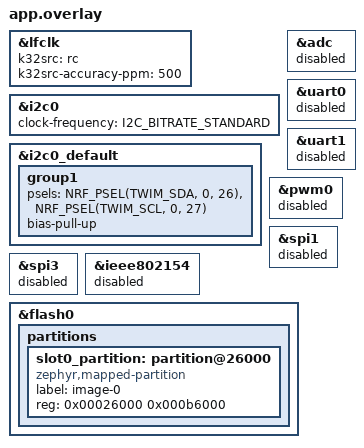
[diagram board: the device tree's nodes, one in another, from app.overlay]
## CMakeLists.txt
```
cmake_minimum_required(VERSION 3.20.0)
find_package(Zephyr REQUIRED HINTS $ENV{ZEPHYR_BASE})
project(nu40_ble_lcd)
target_include_directories(app PRIVATE include ../wireless_lcd_common/include)
target_sources(app PRIVATE src/main.c src/lcd_device.c src/lcd_command.c)
target_sources_ifdef(CONFIG_LCD_SSD1306_PROFILE app PRIVATE src/oled_device.c)
```

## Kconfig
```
mainmenu "NU40 BLE LCD"

config LCD_SSD1306_PROFILE
	bool "Enable an explicitly verified SSD1306 128x32 I2C OLED profile"
	default n
	help
	  SSD1306 only: 128x32, 16x4 ASCII cells, internal charge pump, no reset GPIO.
	  Confirm actual controller, geometry, address and voltage before enabling.

config LCD_PCF8574_PROFILE
	bool "Enable an explicitly verified HD44780 / PCF8574 backpack profile"
	default n
	depends on !LCD_SSD1306_PROFILE
	help
	  Enable only after confirming the LCD controller, supply/logic levels,
	  expander address, pin mapping, geometry and physical I2C wiring.

config LCD_COLUMNS
	int "LCD columns"
	default 16
	range 1 20

config LCD_ROWS
	int "LCD rows (driver supports 1, 2, or 4)"
	default 2
	range 1 4

config LCD_I2C_ADDRESS
	hex "Explicitly configured I2C display address"
	default 0x27
	range 0x20 0x3f

config LCD_RS_BIT
	int "Expander bit for RS"
	default 0
	range 0 7
config LCD_RW_BIT
	int "Expander bit for RW (always driven LOW)"
	default 1
	range 0 7
config LCD_ENABLE_BIT
	int "Expander bit for Enable"
	default 2
	range 0 7
config LCD_BACKLIGHT_BIT
	int "Expander bit for backlight"
	default 3
	range 0 7
config LCD_DB4_BIT
	int "Expander bit for DB4"
	default 4
	range 0 7
config LCD_DB5_BIT
	int "Expander bit for DB5"
	default 5
	range 0 7
config LCD_DB6_BIT
	int "Expander bit for DB6"
	default 6
	range 0 7
config LCD_DB7_BIT
	int "Expander bit for DB7"
	default 7
	range 0 7
config LCD_BACKLIGHT_ACTIVE_HIGH
	bool "Backlight is active HIGH"
	default y

config LCD_LEGACY_DFU
	bool "Permit reset entry into verified Adafruit 0.9.1 legacy BLE DFU"
	default n
	help
	  Only enable after verifying this board's preserved S140/Adafruit OTA
	  bootloader and recovery path. This enables a reset trigger, not an OTA
	  transfer implementation, signatures, rollback, or MCUboot support.

source "Kconfig.zephyr"
```

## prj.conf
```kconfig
CONFIG_GPIO=y
CONFIG_I2C=y
CONFIG_PINCTRL=y
CONFIG_CONSOLE=y
CONFIG_PRINTK=y
CONFIG_BT=y
CONFIG_BT_PERIPHERAL=y
CONFIG_BT_DEVICE_NAME="MZSZ-LCD"
CONFIG_BT_MAX_CONN=1
CONFIG_BT_SMP=n
CONFIG_MAIN_STACK_SIZE=4096
CONFIG_SYSTEM_WORKQUEUE_STACK_SIZE=2048
CONFIG_BUILD_OUTPUT_UF2=y
CONFIG_USE_DT_CODE_PARTITION=y
CONFIG_LCD_PCF8574_PROFILE=n
CONFIG_LCD_SSD1306_PROFILE=n
CONFIG_LCD_LEGACY_DFU=n
```

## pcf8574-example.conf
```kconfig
# EXAMPLE ONLY: confirm controller, geometry, address, mapping and voltage first.
CONFIG_LCD_PCF8574_PROFILE=y
CONFIG_LCD_COLUMNS=16
CONFIG_LCD_ROWS=2
CONFIG_LCD_I2C_ADDRESS=0x27
CONFIG_LCD_RS_BIT=0
CONFIG_LCD_RW_BIT=1
CONFIG_LCD_ENABLE_BIT=2
CONFIG_LCD_BACKLIGHT_BIT=3
CONFIG_LCD_DB4_BIT=4
CONFIG_LCD_DB5_BIT=5
CONFIG_LCD_DB6_BIT=6
CONFIG_LCD_DB7_BIT=7
CONFIG_LCD_BACKLIGHT_ACTIVE_HIGH=y
```

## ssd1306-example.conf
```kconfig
# EXAMPLE ONLY: confirm SSD1306, 128x32, 0x3C and compatible I2C logic levels.
CONFIG_LCD_SSD1306_PROFILE=y
CONFIG_LCD_PCF8574_PROFILE=n
CONFIG_LCD_COLUMNS=16
CONFIG_LCD_ROWS=4
CONFIG_LCD_I2C_ADDRESS=0x3c
```

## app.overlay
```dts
/* Legacy NRF52BOOT 0.9.1 / S140 6.1.1 only. Preserve MBR, SD, NVS and bootloader. */
&lfclk {
	k32src = "rc";
	k32src-accuracy-ppm = <500>;
};

&i2c0 {
	status = "okay";
	clock-frequency = <I2C_BITRATE_STANDARD>;
};
&i2c0_default {
	group1 {
		psels = <NRF_PSEL(TWIM_SDA, 0, 26)>, <NRF_PSEL(TWIM_SCL, 0, 27)>;
		bias-pull-up;
	};
};

&adc { status = "disabled"; };
&uart0 { status = "disabled"; };
&uart1 { status = "disabled"; };
&pwm0 { status = "disabled"; };
&spi1 { status = "disabled"; };
&spi3 { status = "disabled"; };
&ieee802154 { status = "disabled"; };

&flash0 {
	partitions {
		/delete-node/ partition@1000;
		/delete-node/ partition@10000;
		/delete-node/ partition@76000;
		slot0_partition: partition@26000 {
			compatible = "zephyr,mapped-partition";
			label = "image-0";
			reg = <0x00026000 0x000b6000>;
		};
	};
};
```

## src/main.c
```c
#include <errno.h>
#include <string.h>

#include <zephyr/bluetooth/bluetooth.h>
#include <zephyr/bluetooth/conn.h>
#include <zephyr/bluetooth/gatt.h>
#include <zephyr/bluetooth/uuid.h>
#include <zephyr/device.h>
#include <zephyr/drivers/i2c.h>
#include <zephyr/kernel.h>
#include <zephyr/sys/atomic.h>
#include <zephyr/sys/printk.h>

#include "lcd_command.h"
#include "lcd_device.h"
#include "oled_device.h"

#if defined(CONFIG_LCD_LEGACY_DFU)
#include <hal/nrf_power.h>
#endif

#define LCD_ENCODE_UUID(...) BT_UUID_128_ENCODE(__VA_ARGS__)
#define LCD_SERVICE_UUID_VAL LCD_ENCODE_UUID(LCD_SERVICE_UUID_PARTS)
#define LCD_COMMAND_UUID_VAL LCD_ENCODE_UUID(LCD_COMMAND_UUID_PARTS)
#define LCD_STATUS_UUID_VAL LCD_ENCODE_UUID(LCD_STATUS_UUID_PARTS)
#define STATUS_ATTR_INDEX 4
#define LCD_PROFILE_CONFIGURED (IS_ENABLED(CONFIG_LCD_PCF8574_PROFILE) || \
				IS_ENABLED(CONFIG_LCD_SSD1306_PROFILE))
BUILD_ASSERT(CONFIG_LCD_ROWS == 1 || CONFIG_LCD_ROWS == 2 || CONFIG_LCD_ROWS == 4,
	     "Text profiles support 1, 2, or 4 rows");
BUILD_ASSERT(LCD_COMMAND_MAX_SIZE <= 20 && LCD_STATUS_SIZE <= 20,
	     "LCD protocol must fit the default ATT MTU");

struct pending_command {
	struct lcd_command command;
	struct bt_conn *connection;
	atomic_val_t generation;
};

K_MSGQ_DEFINE(command_queue, sizeof(struct pending_command), 4, 4);
static atomic_t connection_generation;
static struct k_spinlock status_lock;
#if defined(CONFIG_LCD_SSD1306_PROFILE)
static struct oled_device oled;
BUILD_ASSERT(CONFIG_LCD_COLUMNS == OLED_COLUMNS && CONFIG_LCD_ROWS == OLED_ROWS,
	     "SSD1306 128x32 profile requires 16x4 text cells");
#else
static struct lcd_device lcd;
#endif
static uint8_t latest_status[LCD_STATUS_SIZE] = {
	LCD_PROTOCOL_VERSION, LCD_OP_STATUS, 0, 0, LCD_RESULT_UNCONFIGURED, 0, 0, 0,
};

static const struct bt_uuid_128 service_uuid = BT_UUID_INIT_128(LCD_SERVICE_UUID_VAL);
static const struct bt_uuid_128 command_uuid = BT_UUID_INIT_128(LCD_COMMAND_UUID_VAL);
static const struct bt_uuid_128 status_uuid = BT_UUID_INIT_128(LCD_STATUS_UUID_VAL);

static ssize_t read_status(struct bt_conn *conn, const struct bt_gatt_attr *attr,
			   void *buffer, uint16_t length, uint16_t offset)
{
	uint8_t snapshot[LCD_STATUS_SIZE];
	k_spinlock_key_t key = k_spin_lock(&status_lock);

	memcpy(snapshot, latest_status, sizeof(snapshot));
	k_spin_unlock(&status_lock, key);
	return bt_gatt_attr_read(conn, attr, buffer, length, offset, snapshot, sizeof(snapshot));
}

static ssize_t write_command(struct bt_conn *conn, const struct bt_gatt_attr *attr,
			     const void *buffer, uint16_t length, uint16_t offset,
			     uint8_t flags)
{
	struct pending_command item = {0};
	int rc;

	ARG_UNUSED(attr);
	if (offset != 0) {
		return BT_GATT_ERR(BT_ATT_ERR_INVALID_OFFSET);
	}
	if (flags & (BT_GATT_WRITE_FLAG_PREPARE | BT_GATT_WRITE_FLAG_EXECUTE)) {
		return BT_GATT_ERR(BT_ATT_ERR_NOT_SUPPORTED);
	}
	if (length < LCD_COMMAND_HEADER_SIZE || length > LCD_COMMAND_MAX_SIZE) {
		return BT_GATT_ERR(BT_ATT_ERR_INVALID_ATTRIBUTE_LEN);
	}
	rc = lcd_command_parse(buffer, length, CONFIG_LCD_COLUMNS, CONFIG_LCD_ROWS,
			       &item.command);
	if (rc != 0) {
		return BT_GATT_ERR(BT_ATT_ERR_VALUE_NOT_ALLOWED);
	}
	item.connection = bt_conn_ref(conn);
	item.generation = atomic_get(&connection_generation);
	rc = k_msgq_put(&command_queue, &item, K_NO_WAIT);
	if (rc != 0) {
		bt_conn_unref(item.connection);
		return BT_GATT_ERR(BT_ATT_ERR_INSUFFICIENT_RESOURCES);
	}
	return length;
}

BT_GATT_SERVICE_DEFINE(lcd_service,
	BT_GATT_PRIMARY_SERVICE(&service_uuid),
	BT_GATT_CHARACTERISTIC(&command_uuid.uuid, BT_GATT_CHRC_WRITE,
			       BT_GATT_PERM_WRITE, NULL, write_command, NULL),
	BT_GATT_CHARACTERISTIC(&status_uuid.uuid, BT_GATT_CHRC_READ | BT_GATT_CHRC_NOTIFY,
			       BT_GATT_PERM_READ, read_status, NULL, NULL),
	BT_GATT_CCC(NULL, BT_GATT_PERM_READ | BT_GATT_PERM_WRITE),
);

static const struct bt_data advertising[] = {
	BT_DATA_BYTES(BT_DATA_FLAGS, BT_LE_AD_GENERAL | BT_LE_AD_NO_BREDR),
	BT_DATA_BYTES(BT_DATA_UUID128_ALL, LCD_SERVICE_UUID_VAL),
};
static const struct bt_data scan_response[] = {
	BT_DATA(BT_DATA_NAME_COMPLETE, CONFIG_BT_DEVICE_NAME, sizeof(CONFIG_BT_DEVICE_NAME) - 1),
};

static void advertising_work(struct k_work *work)
{
	int rc;

	ARG_UNUSED(work);
	rc = bt_le_adv_start(BT_LE_ADV_CONN_FAST_1, advertising, ARRAY_SIZE(advertising),
			     scan_response, ARRAY_SIZE(scan_response));
	if (rc != 0 && rc != -EALREADY) {
		printk("LCD BLE advertising error=%d\n", rc);
	}
}
K_WORK_DEFINE(advertising_restart, advertising_work);

static void connected(struct bt_conn *conn, uint8_t error)
{
	ARG_UNUSED(conn);
	if (error == 0) {
		atomic_inc(&connection_generation);
		printk("LCD BLE connected\n");
	} else {
		k_work_submit(&advertising_restart);
	}
}

static void disconnected(struct bt_conn *conn, uint8_t reason)
{
	ARG_UNUSED(conn);
	atomic_inc(&connection_generation);
	printk("LCD BLE disconnected reason=%u; queued commands expire\n", reason);
}

static void recycled(void)
{
	/* Wait for the old connection references to be released before advertising. */
	k_work_submit(&advertising_restart);
}

BT_CONN_CB_DEFINE(connection_callbacks) = {
	.connected = connected,
	.disconnected = disconnected,
	.recycled = recycled,
};

static bool display_ready(void)
{
#if defined(CONFIG_LCD_SSD1306_PROFILE)
	return oled.initialized;
#else
	return lcd.initialized;
#endif
}

static void update_status(uint8_t opcode, uint16_t sequence, uint8_t result)
{
	uint8_t status[LCD_STATUS_SIZE] = {
		LCD_PROTOCOL_VERSION, opcode, 0, 0, result, 0, 0, 0,
	};
	k_spinlock_key_t key;

	lcd_put_le16(status + 2, sequence);
	if (display_ready()) {
		status[5] |= LCD_FLAG_READY;
	}
	if (IS_ENABLED(CONFIG_LCD_LEGACY_DFU)) {
		status[5] |= LCD_FLAG_DFU_CAPABLE;
	}
	if (LCD_PROFILE_CONFIGURED) {
		status[6] = CONFIG_LCD_COLUMNS;
		status[7] = CONFIG_LCD_ROWS;
	}
	key = k_spin_lock(&status_lock);
	memcpy(latest_status, status, sizeof(status));
	k_spin_unlock(&status_lock, key);
}

#if defined(CONFIG_LCD_PCF8574_PROFILE) || defined(CONFIG_LCD_SSD1306_PROFILE)
static const struct device *const i2c_bus = DEVICE_DT_GET(DT_NODELABEL(i2c0));
#if defined(CONFIG_LCD_PCF8574_PROFILE)
static const struct lcd_config profile = {
	.address = CONFIG_LCD_I2C_ADDRESS,
	.columns = CONFIG_LCD_COLUMNS,
	.rows = CONFIG_LCD_ROWS,
	.rs_bit = CONFIG_LCD_RS_BIT,
	.rw_bit = CONFIG_LCD_RW_BIT,
	.enable_bit = CONFIG_LCD_ENABLE_BIT,
	.backlight_bit = CONFIG_LCD_BACKLIGHT_BIT,
	.data_bits = {CONFIG_LCD_DB4_BIT, CONFIG_LCD_DB5_BIT, CONFIG_LCD_DB6_BIT, CONFIG_LCD_DB7_BIT},
	.backlight_active_high = IS_ENABLED(CONFIG_LCD_BACKLIGHT_ACTIVE_HIGH),
};
#endif

static int lcd_i2c_write(void *context, uint8_t address, const uint8_t *bytes, size_t length)
{
	return i2c_write(context, bytes, length, address);
}

static void lcd_delay(void *context, uint32_t microseconds)
{
	ARG_UNUSED(context);
	k_usleep(microseconds);
}
#endif

static int initialize_lcd(void)
{
#if defined(CONFIG_LCD_PCF8574_PROFILE) || defined(CONFIG_LCD_SSD1306_PROFILE)
	const struct lcd_bus bus = {
		.context = (void *)i2c_bus,
		.write = lcd_i2c_write,
		.delay_us = lcd_delay,
	};
	if (!device_is_ready(i2c_bus)) {
		return -ENODEV;
	}
#if defined(CONFIG_LCD_SSD1306_PROFILE)
	return oled_device_initialize(&oled, CONFIG_LCD_I2C_ADDRESS, &bus);
#else
	return lcd_device_initialize(&lcd, &profile, &bus);
#endif
#else
	return -ENOTSUP;
#endif
}

#if defined(CONFIG_LCD_LEGACY_DFU)
K_SEM_DEFINE(dfu_ack_sent, 0, 1);
static atomic_t dfu_notification_generation;

static void dfu_notify_complete(struct bt_conn *conn, void *user_data)
{
	ARG_UNUSED(conn);
	if ((uintptr_t)user_data == (uintptr_t)atomic_get(&dfu_notification_generation)) {
		k_sem_give(&dfu_ack_sent);
	}
}

static int enter_legacy_dfu(struct bt_conn *conn)
{
	struct bt_gatt_notify_params params = {
		.attr = &lcd_service.attrs[STATUS_ATTR_INDEX],
		.data = latest_status,
		.len = sizeof(latest_status),
		.func = dfu_notify_complete,
	};
	int rc;

	if (!bt_gatt_is_subscribed(conn, params.attr, BT_GATT_CCC_NOTIFY)) {
		return -EACCES;
	}
	/* A late callback from a timed-out attempt must not acknowledge a retry. */
	params.user_data = (void *)(uintptr_t)(atomic_inc(&dfu_notification_generation) + 1);
	k_sem_reset(&dfu_ack_sent);
	rc = bt_gatt_notify_cb(conn, &params);
	if (rc != 0 || k_sem_take(&dfu_ack_sent, K_SECONDS(2)) != 0) {
		return rc != 0 ? rc : -ETIMEDOUT;
	}
	/* Cold reset lets the preserved bootloader initialize its own S140 stack. */
	NRF_POWER->GPREGRET = 0xa8;
	NVIC_SystemReset();
	return -EIO;
}
#endif

static uint8_t apply_command(const struct lcd_command *command)
{
	int rc;

	if (command->opcode == LCD_OP_STATUS) {
		return LCD_RESULT_OK;
	}
	if (command->opcode == LCD_OP_ENTER_DFU) {
		return IS_ENABLED(CONFIG_LCD_LEGACY_DFU) ? LCD_RESULT_OK : LCD_RESULT_DFU_DISABLED;
	}
	if (!LCD_PROFILE_CONFIGURED) {
		return LCD_RESULT_UNCONFIGURED;
	}
	/* No implicit clear/reinitialize on an I2C error: preserve truthful status. */
	if (!display_ready()) {
		return LCD_RESULT_IO;
	}
	switch (command->opcode) {
	case LCD_OP_CLEAR:
#if defined(CONFIG_LCD_SSD1306_PROFILE)
		rc = oled_device_clear(&oled);
#else
		rc = lcd_device_clear(&lcd);
#endif
		break;
	case LCD_OP_WRITE:
#if defined(CONFIG_LCD_SSD1306_PROFILE)
		rc = oled_device_write(&oled, command->row, command->column,
				       command->text, command->length);
#else
		rc = lcd_device_write(&lcd, command->row, command->column,
				      command->text, command->length);
#endif
		break;
	case LCD_OP_BACKLIGHT:
#if defined(CONFIG_LCD_SSD1306_PROFILE)
		rc = oled_device_display(&oled, command->backlight != 0);
#else
		rc = lcd_device_backlight(&lcd, command->backlight != 0);
#endif
		break;
	default:
		return LCD_RESULT_INVALID;
	}
	return rc == 0 ? LCD_RESULT_OK : LCD_RESULT_IO;
}

int main(void)
{
	struct pending_command item;
	int rc = initialize_lcd();

	printk("NU40 BLE LCD v1; legacy 0x26000..0xDC000; LCD profile=%s init=%d DFU=%s\n",
	       LCD_PROFILE_CONFIGURED ? "configured" : "unconfigured", rc,
	       IS_ENABLED(CONFIG_LCD_LEGACY_DFU) ? "enabled" : "disabled");
	update_status(LCD_OP_STATUS, 0, rc == 0 ? LCD_RESULT_OK :
		(LCD_PROFILE_CONFIGURED ? LCD_RESULT_IO : LCD_RESULT_UNCONFIGURED));
	rc = bt_enable(NULL);
	if (rc != 0) {
		printk("LCD BLE initialization error=%d\n", rc);
		return rc;
	}
	k_work_submit(&advertising_restart);
	while (true) {
		struct bt_conn_info info;
		uint8_t result;

		k_msgq_get(&command_queue, &item, K_FOREVER);
		if (item.generation != atomic_get(&connection_generation) ||
		    bt_conn_get_info(item.connection, &info) != 0 ||
		    info.state != BT_CONN_STATE_CONNECTED) {
			bt_conn_unref(item.connection);
			continue;
		}
		result = apply_command(&item.command);
		update_status(item.command.opcode, item.command.sequence, result);
#if defined(CONFIG_LCD_LEGACY_DFU)
		if (item.command.opcode == LCD_OP_ENTER_DFU && result == LCD_RESULT_OK) {
			rc = enter_legacy_dfu(item.connection);
			printk("LCD DFU entry aborted error=%d\n", rc);
			update_status(item.command.opcode, item.command.sequence, LCD_RESULT_IO);
		}
#endif
		rc = bt_gatt_notify(item.connection, &lcd_service.attrs[STATUS_ATTR_INDEX],
				    latest_status, sizeof(latest_status));
		printk("LCD applied seq=%u op=%u result=%u notify=%d\n",
		       item.command.sequence, item.command.opcode, latest_status[4], rc);
		bt_conn_unref(item.connection);
	}
	return 0;
}
```

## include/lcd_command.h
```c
#ifndef NU40_LCD_COMMAND_H
#define NU40_LCD_COMMAND_H

#include "lcd_protocol.h"

struct lcd_command {
	uint8_t opcode;
	uint16_t sequence;
	uint8_t row;
	uint8_t column;
	uint8_t length;
	uint8_t text[LCD_TEXT_CHUNK_MAX];
	uint8_t backlight;
};

/* Returns zero on success, negative errno on invalid wire data/geometry. */
int lcd_command_parse(const void *bytes, size_t length, uint8_t columns,
		      uint8_t rows, struct lcd_command *command);

#endif
```

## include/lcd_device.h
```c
#ifndef NU40_LCD_DEVICE_H
#define NU40_LCD_DEVICE_H

#include <stdbool.h>
#include <stddef.h>
#include <stdint.h>

/* Explicit HD44780 + PCF8574/PCF8574A write-only hardware profile. */
struct lcd_config {
	uint8_t address;
	uint8_t columns;
	uint8_t rows;
	uint8_t rs_bit;
	uint8_t rw_bit;
	uint8_t enable_bit;
	uint8_t backlight_bit;
	uint8_t data_bits[4]; /* HD44780 DB4, DB5, DB6, DB7. */
	bool backlight_active_high;
};

struct lcd_bus {
	void *context;
	int (*write)(void *context, uint8_t address, const uint8_t *bytes, size_t length);
	void (*delay_us)(void *context, uint32_t microseconds);
};

struct lcd_device {
	struct lcd_config config;
	struct lcd_bus bus;
	bool initialized;
	bool backlight;
};

int lcd_device_initialize(struct lcd_device *lcd, const struct lcd_config *config,
			  const struct lcd_bus *bus);
int lcd_device_clear(struct lcd_device *lcd);
int lcd_device_write(struct lcd_device *lcd, uint8_t row, uint8_t column,
		     const uint8_t *text, size_t length);
int lcd_device_backlight(struct lcd_device *lcd, bool enabled);

#endif
```

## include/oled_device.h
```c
#ifndef NU40_OLED_DEVICE_H
#define NU40_OLED_DEVICE_H

#include "lcd_device.h"

#define OLED_COLUMNS 16U
#define OLED_ROWS 4U

struct oled_device {
	struct lcd_bus bus;
	uint8_t address;
	bool initialized;
};

/* SSD1306 only: 128x32, internal charge pump, 8x8 text cells, no reset GPIO. */
int oled_device_initialize(struct oled_device *oled, uint8_t address, const struct lcd_bus *bus);
int oled_device_clear(struct oled_device *oled);
int oled_device_write(struct oled_device *oled, uint8_t row, uint8_t column,
		      const uint8_t *text, size_t length);
int oled_device_display(struct oled_device *oled, bool enabled);

#endif
```

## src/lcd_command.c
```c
#include "lcd_command.h"

#include <errno.h>
#include <string.h>

int lcd_command_parse(const void *bytes, size_t length, uint8_t columns,
		      uint8_t rows, struct lcd_command *command)
{
	const uint8_t *wire = bytes;
	struct lcd_command parsed = {0};

	if (!wire || !command || length < LCD_COMMAND_HEADER_SIZE ||
	    length > LCD_COMMAND_MAX_SIZE || wire[0] != LCD_PROTOCOL_VERSION ||
	    columns == 0 || columns > LCD_MAX_COLUMNS ||
	    !(rows == 1 || rows == 2 || rows == 4)) {
		return -EINVAL;
	}
	parsed.opcode = wire[1];
	parsed.sequence = lcd_get_le16(wire + 2);
	switch (parsed.opcode) {
	case LCD_OP_STATUS:
	case LCD_OP_CLEAR:
		if (length != LCD_COMMAND_HEADER_SIZE) {
			return -EINVAL;
		}
		break;
	case LCD_OP_WRITE:
		if (length <= LCD_WRITE_PREFIX_SIZE) {
			return -EINVAL;
		}
		parsed.row = wire[4];
		parsed.column = wire[5];
		parsed.length = length - LCD_WRITE_PREFIX_SIZE;
		if (parsed.row >= rows || parsed.column >= columns ||
		    parsed.length > columns - parsed.column) {
			return -ERANGE;
		}
		for (size_t i = 0; i < parsed.length; ++i) {
			if (wire[LCD_WRITE_PREFIX_SIZE + i] < 0x20 ||
			    wire[LCD_WRITE_PREFIX_SIZE + i] > 0x7e) {
				return -EINVAL;
			}
		}
		memcpy(parsed.text, wire + LCD_WRITE_PREFIX_SIZE, parsed.length);
		break;
	case LCD_OP_BACKLIGHT:
		if (length != LCD_COMMAND_HEADER_SIZE + 1 || wire[4] > 1) {
			return -EINVAL;
		}
		parsed.backlight = wire[4];
		break;
	case LCD_OP_ENTER_DFU:
		if (length != LCD_COMMAND_HEADER_SIZE + 4 ||
		    memcmp(wire + LCD_COMMAND_HEADER_SIZE, "DFU!", 4) != 0) {
			return -EINVAL;
		}
		break;
	default:
		return -ENOTSUP;
	}
	*command = parsed;
	return 0;
}
```

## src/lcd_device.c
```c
#include "lcd_device.h"

#include <errno.h>

static int validate_config(const struct lcd_config *config, const struct lcd_bus *bus)
{
	uint16_t used = 0;
	uint8_t bits[8];

	if (!config || !bus || !bus->write || !bus->delay_us ||
	    !((config->address >= 0x20 && config->address <= 0x27) ||
	      (config->address >= 0x38 && config->address <= 0x3f)) ||
	    config->columns == 0 || config->columns > 40 ||
	    !(config->rows == 1 || config->rows == 2 || config->rows == 4) ||
	    (unsigned int)config->rows * config->columns > 80) {
		return -EINVAL;
	}
	bits[0] = config->rs_bit;
	bits[1] = config->rw_bit;
	bits[2] = config->enable_bit;
	bits[3] = config->backlight_bit;
	for (size_t i = 0; i < 4; ++i) {
		bits[4 + i] = config->data_bits[i];
	}
	for (size_t i = 0; i < 8; ++i) {
		if (bits[i] > 7 || (used & (1U << bits[i]))) {
			return -EINVAL;
		}
		used |= 1U << bits[i];
	}
	return 0;
}

static uint8_t backlight_mask(const struct lcd_device *lcd)
{
	return lcd->backlight == lcd->config.backlight_active_high ?
		(1U << lcd->config.backlight_bit) : 0;
}

static int write_bus(struct lcd_device *lcd, const uint8_t *bytes, size_t length)
{
	int rc = lcd->bus.write(lcd->bus.context, lcd->config.address, bytes, length);

	if (rc != 0) {
		lcd->initialized = false;
		return rc < 0 ? rc : -EIO;
	}
	return 0;
}

static int write_nibble(struct lcd_device *lcd, uint8_t nibble, bool data)
{
	uint8_t value = backlight_mask(lcd);
	uint8_t bytes[3];

	if (data) {
		value |= 1U << lcd->config.rs_bit;
	}
	for (size_t i = 0; i < 4; ++i) {
		if (nibble & (1U << i)) {
			value |= 1U << lcd->config.data_bits[i];
		}
	}
	/* RW stays LOW. Standard-speed I2C provides >450 ns E-high time. */
	bytes[0] = value;
	bytes[1] = value | (1U << lcd->config.enable_bit);
	bytes[2] = value;
	return write_bus(lcd, bytes, sizeof(bytes));
}

static int write_byte(struct lcd_device *lcd, uint8_t byte, bool data)
{
	int rc = write_nibble(lcd, byte >> 4, data);

	if (rc == 0) {
		rc = write_nibble(lcd, byte & 0x0f, data);
	}
	if (rc == 0) {
		lcd->bus.delay_us(lcd->bus.context,
			(!data && (byte == 0x01 || byte == 0x02)) ? 2000 : 50);
	}
	return rc;
}

int lcd_device_initialize(struct lcd_device *lcd, const struct lcd_config *config,
			  const struct lcd_bus *bus)
{
	int rc;
	uint8_t latch;
	static const uint8_t nibbles[] = {3, 3, 3, 2};
	static const uint32_t waits[] = {4500, 150, 150, 150};
	uint8_t commands[5];

	if (!lcd) {
		return -EINVAL;
	}
	lcd->initialized = false;
	rc = validate_config(config, bus);
	if (rc != 0) {
		return rc;
	}
	lcd->config = *config;
	lcd->bus = *bus;
	lcd->backlight = true;
	latch = backlight_mask(lcd);
	rc = write_bus(lcd, &latch, 1);
	if (rc != 0) {
		return rc;
	}
	lcd->bus.delay_us(lcd->bus.context, 50000);
	for (size_t i = 0; i < sizeof(nibbles); ++i) {
		rc = write_nibble(lcd, nibbles[i], false);
		if (rc != 0) {
			return rc;
		}
		lcd->bus.delay_us(lcd->bus.context, waits[i]);
	}
	commands[0] = config->rows > 1 ? 0x28 : 0x20;
	commands[1] = 0x08;
	commands[2] = 0x01;
	commands[3] = 0x06;
	commands[4] = 0x0c;
	for (size_t i = 0; i < sizeof(commands); ++i) {
		rc = write_byte(lcd, commands[i], false);
		if (rc != 0) {
			return rc;
		}
	}
	lcd->initialized = true;
	return 0;
}

int lcd_device_clear(struct lcd_device *lcd)
{
	if (!lcd || !lcd->initialized) {
		return -ENODEV;
	}
	return write_byte(lcd, 0x01, false);
}

int lcd_device_write(struct lcd_device *lcd, uint8_t row, uint8_t column,
		     const uint8_t *text, size_t length)
{
	uint8_t address;
	int rc;

	if (!lcd || !lcd->initialized) {
		return -ENODEV;
	}
	if (!text || length == 0 || row >= lcd->config.rows ||
	    column >= lcd->config.columns || length > lcd->config.columns - column) {
		return -EINVAL;
	}
	for (size_t i = 0; i < length; ++i) {
		if (text[i] < 0x20 || text[i] > 0x7e) {
			return -EINVAL;
		}
	}
	address = column + (row % 2 ? 0x40 : 0x00) +
		(row >= 2 ? lcd->config.columns : 0);
	rc = write_byte(lcd, 0x80 | address, false);
	for (size_t i = 0; rc == 0 && i < length; ++i) {
		rc = write_byte(lcd, text[i], true);
	}
	return rc;
}

int lcd_device_backlight(struct lcd_device *lcd, bool enabled)
{
	uint8_t latch;

	if (!lcd || !lcd->initialized) {
		return -ENODEV;
	}
	lcd->backlight = enabled;
	latch = backlight_mask(lcd);
	return write_bus(lcd, &latch, 1);
}
```

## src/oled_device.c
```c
#include "oled_device.h"

#include <errno.h>
#include <string.h>

#include "oled_font.h"

static int write_bus(struct oled_device *oled, const uint8_t *bytes, size_t length)
{
	int rc = oled->bus.write(oled->bus.context, oled->address, bytes, length);

	if (rc != 0) {
		oled->initialized = false;
		return rc < 0 ? rc : -EIO;
	}
	return 0;
}

static int address_window(struct oled_device *oled, uint8_t row, uint8_t column,
			  uint8_t pixel_count)
{
	const uint8_t commands[] = {
		0x00, 0x21, column, column + pixel_count - 1, 0x22, row, row,
	};
	return write_bus(oled, commands, sizeof(commands));
}

static int clear_pages(struct oled_device *oled)
{
	const uint8_t zeroes[33] = {0x40};
	int rc;

	for (uint8_t row = 0; row < OLED_ROWS; ++row) {
		rc = address_window(oled, row, 0, 128);
		if (rc != 0) {
			return rc;
		}
		for (uint8_t chunk = 0; chunk < 4; ++chunk) {
			rc = write_bus(oled, zeroes, sizeof(zeroes));
			if (rc != 0) {
				return rc;
			}
		}
	}
	return 0;
}

int oled_device_initialize(struct oled_device *oled, uint8_t address, const struct lcd_bus *bus)
{
	/* SSD1306 128x32 sequential COM pins and internal charge pump profile. */
	const uint8_t commands[] = {
		0x00, 0xae, 0xd5, 0x80, 0xa8, 0x1f, 0xd3, 0x00, 0x40,
		0x8d, 0x14, 0x20, 0x00, 0xa1, 0xc8, 0xda, 0x02,
		0x81, 0x8f, 0xd9, 0xf1, 0xdb, 0x40, 0xa4, 0xa6, 0x2e,
	};
	const uint8_t on[] = {0x00, 0xaf};
	int rc;

	if (!oled) {
		return -EINVAL;
	}
	oled->initialized = false;
	if (!bus || !bus->write || !bus->delay_us || (address != 0x3c && address != 0x3d)) {
		return -EINVAL;
	}
	oled->address = address;
	oled->bus = *bus;
	oled->bus.delay_us(oled->bus.context, 100000);
	rc = write_bus(oled, commands, sizeof(commands));
	if (rc == 0) {
		rc = clear_pages(oled);
	}
	if (rc == 0) {
		rc = write_bus(oled, on, sizeof(on));
	}
	if (rc == 0) {
		oled->initialized = true;
	}
	return rc;
}

int oled_device_clear(struct oled_device *oled)
{
	if (!oled || !oled->initialized) {
		return -ENODEV;
	}
	return clear_pages(oled);
}

int oled_device_write(struct oled_device *oled, uint8_t row, uint8_t column,
		      const uint8_t *text, size_t length)
{
	int rc;

	if (!oled || !oled->initialized) {
		return -ENODEV;
	}
	if (!text || length == 0 || row >= OLED_ROWS || column >= OLED_COLUMNS ||
	    length > OLED_COLUMNS - column) {
		return -EINVAL;
	}
	for (size_t i = 0; i < length; ++i) {
		if (text[i] < 0x20 || text[i] > 0x7e) {
			return -EINVAL;
		}
	}
	rc = address_window(oled, row, column * 8U, length * 8U);
	for (size_t i = 0; rc == 0 && i < length; ++i) {
		uint8_t glyph[9] = {0x40};

		/* Five columns centered in each independent 8x8 cell; blank padding. */
		for (size_t x = 0; x < 5; ++x) {
			glyph[x + 2] = oled_font_5x5[text[i] - 0x20][x] << 1;
		}
		rc = write_bus(oled, glyph, sizeof(glyph));
	}
	return rc;
}

int oled_device_display(struct oled_device *oled, bool enabled)
{
	const uint8_t command[] = {0x00, enabled ? 0xaf : 0xae};

	if (!oled || !oled->initialized) {
		return -ENODEV;
	}
	return write_bus(oled, command, sizeof(command));
}
```

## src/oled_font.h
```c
/* Copyright (c) 2017 Intel Corporation
 * SPDX-License-Identifier: Apache-2.0
 * Converted from Zephyr drivers/display/mb_font.c at 8dafb9a897da.
 * 95 printable ASCII glyphs. Each byte is a vertical 5-pixel column.
 */
static const uint8_t oled_font_5x5[95][5] = {
	{0x00, 0x00, 0x00, 0x00, 0x00}, /* ASCII 32 */
	{0x00, 0x17, 0x00, 0x00, 0x00}, /* ASCII 33 */
	{0x00, 0x03, 0x00, 0x03, 0x00}, /* ASCII 34 */
	{0x0a, 0x1f, 0x0a, 0x1f, 0x0a}, /* ASCII 35 */
	{0x0a, 0x17, 0x15, 0x1d, 0x0a}, /* ASCII 36 */
	{0x13, 0x09, 0x04, 0x12, 0x19}, /* ASCII 37 */
	{0x0a, 0x15, 0x15, 0x0a, 0x10}, /* ASCII 38 */
	{0x00, 0x03, 0x00, 0x00, 0x00}, /* ASCII 39 */
	{0x00, 0x0e, 0x11, 0x00, 0x00}, /* ASCII 40 */
	{0x00, 0x11, 0x0e, 0x00, 0x00}, /* ASCII 41 */
	{0x00, 0x0a, 0x04, 0x0a, 0x00}, /* ASCII 42 */
	{0x00, 0x04, 0x0e, 0x04, 0x00}, /* ASCII 43 */
	{0x00, 0x10, 0x08, 0x00, 0x00}, /* ASCII 44 */
	{0x00, 0x04, 0x04, 0x04, 0x00}, /* ASCII 45 */
	{0x00, 0x08, 0x00, 0x00, 0x00}, /* ASCII 46 */
	{0x10, 0x08, 0x04, 0x02, 0x01}, /* ASCII 47 */
	{0x0e, 0x11, 0x11, 0x0e, 0x00}, /* ASCII 48 */
	{0x00, 0x12, 0x1f, 0x10, 0x00}, /* ASCII 49 */
	{0x19, 0x15, 0x15, 0x12, 0x00}, /* ASCII 50 */
	{0x09, 0x11, 0x15, 0x0b, 0x00}, /* ASCII 51 */
	{0x0c, 0x0a, 0x09, 0x1f, 0x08}, /* ASCII 52 */
	{0x17, 0x15, 0x15, 0x15, 0x09}, /* ASCII 53 */
	{0x08, 0x14, 0x16, 0x15, 0x08}, /* ASCII 54 */
	{0x11, 0x09, 0x05, 0x03, 0x01}, /* ASCII 55 */
	{0x0a, 0x15, 0x15, 0x15, 0x0a}, /* ASCII 56 */
	{0x02, 0x15, 0x0d, 0x05, 0x02}, /* ASCII 57 */
	{0x00, 0x0a, 0x00, 0x00, 0x00}, /* ASCII 58 */
	{0x00, 0x10, 0x0a, 0x00, 0x00}, /* ASCII 59 */
	{0x00, 0x04, 0x0a, 0x11, 0x00}, /* ASCII 60 */
	{0x00, 0x0a, 0x0a, 0x0a, 0x00}, /* ASCII 61 */
	{0x00, 0x11, 0x0a, 0x04, 0x00}, /* ASCII 62 */
	{0x02, 0x01, 0x15, 0x05, 0x02}, /* ASCII 63 */
	{0x0e, 0x11, 0x15, 0x09, 0x0e}, /* ASCII 64 */
	{0x1e, 0x05, 0x05, 0x1e, 0x00}, /* ASCII 65 */
	{0x1f, 0x15, 0x15, 0x0a, 0x00}, /* ASCII 66 */
	{0x0e, 0x11, 0x11, 0x11, 0x00}, /* ASCII 67 */
	{0x1f, 0x11, 0x11, 0x0e, 0x00}, /* ASCII 68 */
	{0x1f, 0x15, 0x15, 0x11, 0x00}, /* ASCII 69 */
	{0x1f, 0x05, 0x05, 0x01, 0x00}, /* ASCII 70 */
	{0x0e, 0x11, 0x11, 0x15, 0x0c}, /* ASCII 71 */
	{0x1f, 0x04, 0x04, 0x1f, 0x00}, /* ASCII 72 */
	{0x11, 0x1f, 0x11, 0x00, 0x00}, /* ASCII 73 */
	{0x09, 0x11, 0x11, 0x0f, 0x01}, /* ASCII 74 */
	{0x1f, 0x04, 0x0a, 0x11, 0x00}, /* ASCII 75 */
	{0x1f, 0x10, 0x10, 0x10, 0x00}, /* ASCII 76 */
	{0x1f, 0x02, 0x04, 0x02, 0x1f}, /* ASCII 77 */
	{0x1f, 0x02, 0x04, 0x08, 0x1f}, /* ASCII 78 */
	{0x0e, 0x11, 0x11, 0x0e, 0x00}, /* ASCII 79 */
	{0x1f, 0x05, 0x05, 0x02, 0x00}, /* ASCII 80 */
	{0x06, 0x09, 0x19, 0x16, 0x00}, /* ASCII 81 */
	{0x1f, 0x05, 0x05, 0x0a, 0x10}, /* ASCII 82 */
	{0x12, 0x15, 0x15, 0x09, 0x00}, /* ASCII 83 */
	{0x01, 0x01, 0x1f, 0x01, 0x01}, /* ASCII 84 */
	{0x0f, 0x10, 0x10, 0x0f, 0x00}, /* ASCII 85 */
	{0x07, 0x08, 0x10, 0x08, 0x07}, /* ASCII 86 */
	{0x1f, 0x08, 0x04, 0x08, 0x1f}, /* ASCII 87 */
	{0x1b, 0x04, 0x04, 0x1b, 0x00}, /* ASCII 88 */
	{0x01, 0x02, 0x1c, 0x02, 0x01}, /* ASCII 89 */
	{0x19, 0x15, 0x13, 0x11, 0x00}, /* ASCII 90 */
	{0x00, 0x1f, 0x11, 0x11, 0x00}, /* ASCII 91 */
	{0x01, 0x02, 0x04, 0x08, 0x10}, /* ASCII 92 */
	{0x00, 0x11, 0x11, 0x1f, 0x00}, /* ASCII 93 */
	{0x00, 0x02, 0x01, 0x02, 0x00}, /* ASCII 94 */
	{0x10, 0x10, 0x10, 0x10, 0x10}, /* ASCII 95 */
	{0x00, 0x01, 0x02, 0x00, 0x00}, /* ASCII 96 */
	{0x0c, 0x12, 0x12, 0x1e, 0x10}, /* ASCII 97 */
	{0x1f, 0x14, 0x14, 0x08, 0x00}, /* ASCII 98 */
	{0x0c, 0x12, 0x12, 0x12, 0x00}, /* ASCII 99 */
	{0x08, 0x14, 0x14, 0x1f, 0x00}, /* ASCII 100 */
	{0x0e, 0x15, 0x15, 0x12, 0x00}, /* ASCII 101 */
	{0x04, 0x1e, 0x05, 0x01, 0x00}, /* ASCII 102 */
	{0x02, 0x15, 0x15, 0x0f, 0x00}, /* ASCII 103 */
	{0x1f, 0x04, 0x04, 0x18, 0x00}, /* ASCII 104 */
	{0x00, 0x1d, 0x00, 0x00, 0x00}, /* ASCII 105 */
	{0x00, 0x10, 0x10, 0x0d, 0x00}, /* ASCII 106 */
	{0x1f, 0x04, 0x0a, 0x10, 0x00}, /* ASCII 107 */
	{0x00, 0x0f, 0x10, 0x10, 0x00}, /* ASCII 108 */
	{0x1e, 0x02, 0x04, 0x02, 0x1e}, /* ASCII 109 */
	{0x1e, 0x02, 0x02, 0x1c, 0x00}, /* ASCII 110 */
	{0x0c, 0x12, 0x12, 0x0c, 0x00}, /* ASCII 111 */
	{0x1e, 0x0a, 0x0a, 0x04, 0x00}, /* ASCII 112 */
	{0x04, 0x0a, 0x0a, 0x1e, 0x00}, /* ASCII 113 */
	{0x1c, 0x02, 0x02, 0x02, 0x00}, /* ASCII 114 */
	{0x10, 0x14, 0x0a, 0x02, 0x00}, /* ASCII 115 */
	{0x00, 0x0f, 0x14, 0x14, 0x10}, /* ASCII 116 */
	{0x0e, 0x10, 0x10, 0x1e, 0x10}, /* ASCII 117 */
	{0x06, 0x08, 0x10, 0x08, 0x06}, /* ASCII 118 */
	{0x1e, 0x10, 0x08, 0x10, 0x1e}, /* ASCII 119 */
	{0x12, 0x0c, 0x0c, 0x12, 0x00}, /* ASCII 120 */
	{0x12, 0x14, 0x08, 0x04, 0x02}, /* ASCII 121 */
	{0x12, 0x1a, 0x16, 0x12, 0x00}, /* ASCII 122 */
	{0x00, 0x04, 0x1f, 0x11, 0x00}, /* ASCII 123 */
	{0x00, 0x1f, 0x00, 0x00, 0x00}, /* ASCII 124 */
	{0x11, 0x1f, 0x04, 0x00, 0x00}, /* ASCII 125 */
	{0x00, 0x04, 0x04, 0x08, 0x08}, /* ASCII 126 */
};
```
